# MKV10Z7 register map
File version: 1.6
Registers are 32-bit, read-write, reset 0x0 unless marked. A register's access mark holds for its fields unless they carry their own. Offsets are from the block's base; [hi:lo] are bit positions; {n}, {i} and the like mark numbered series; 'fields as' and 'values as' point back to an identical list.

## GPIOA — General Purpose Input/Output
Base 0x400FF000; register names take the prefix GPIOA_
0x00 PDOR — Port Data Output Register
  [31:0] PDO — Port Data Output
    0=Logic level 0 is driven on pin, provided pin is configured for general-purpose output; 1=Logic level 1 is driven on pin, provided pin is configured for general-purpose output
0x04 PSOR wo — Port Set Output Register
  [31:0] PTSO — Port Set Output
    0=Corresponding bit in PDORn does not change; 1=Corresponding bit in PDORn is set to logic 1
0x08 PCOR wo — Port Clear Output Register
  [31:0] PTCO — Port Clear Output
    0=Corresponding bit in PDORn does not change; 1=Corresponding bit in PDORn is cleared to logic 0
0x0C PTOR wo — Port Toggle Output Register
  [31:0] PTTO — Port Toggle Output
    0=Corresponding bit in PDORn does not change; 1=Corresponding bit in PDORn is set to the inverse of its existing logic state
0x10 PDIR ro — Port Data Input Register
  [31:0] PDI — Port Data Input
    0=Pin logic level is logic 0, or is not configured for use by digital function; 1=Pin logic level is logic 1
0x14 PDDR — Port Data Direction Register
  [31:0] PDD — Port Data Direction
    0=Pin is configured as general-purpose input, for the GPIO function; 1=Pin is configured as general-purpose output, for the GPIO function

## GPIOB — General Purpose Input/Output
Base 0x400FF040; register names take the prefix GPIOB_
Registers as GPIOA.

## GPIOC — General Purpose Input/Output
Base 0x400FF080; register names take the prefix GPIOC_
Registers as GPIOA.

## GPIOD — General Purpose Input/Output
Base 0x400FF0C0; register names take the prefix GPIOD_
Registers as GPIOA.

## GPIOE — General Purpose Input/Output
Base 0x400FF100; register names take the prefix GPIOE_
Registers as GPIOA.

## MTB — Micro Trace Buffer
Base 0xF0000000; register names take the prefix MTB_
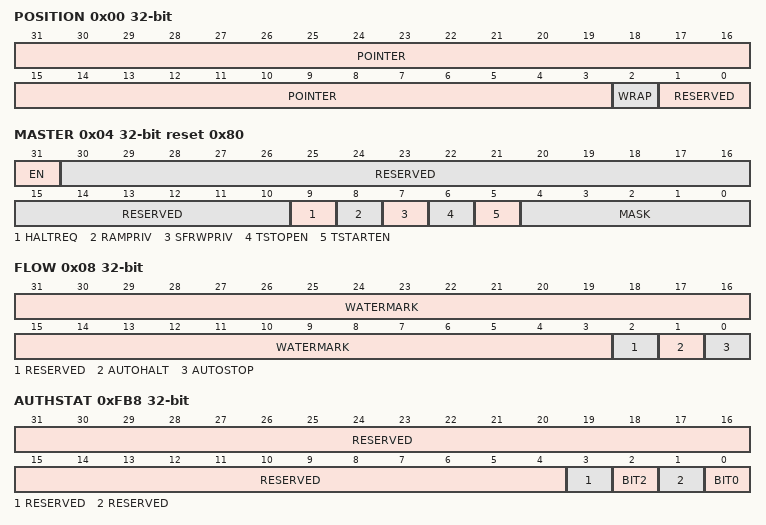
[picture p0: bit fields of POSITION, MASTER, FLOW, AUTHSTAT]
0x00 POSITION (reset mask 0x3) — MTB Position Register
  [31:3] POINTER — Trace Packet Address Pointer[28:0]
  [2] WRAP
  [1:0] RESERVED ro
0x04 MASTER reset 0x80 (reset mask 0xFFFFFFE0) — MTB Master Register
  [31] EN — Main Trace Enable
  [30:10] RESERVED ro
  [9] HALTREQ — Halt Request
  [8] RAMPRIV — RAM Privilege
  [7] SFRWPRIV — Special Function Register Write Privilege
  [6] TSTOPEN — Trace Stop Input Enable
  [5] TSTARTEN — Trace Start Input Enable
  [4:0] MASK
0x08 FLOW (reset mask 0x4) — MTB Flow Register
  [31:3] WATERMARK — WATERMARK[28:0]
  [2] RESERVED ro
  [1] AUTOHALT
  [0] AUTOSTOP
0x0C BASE ro reset not defined — MTB Base Register
  [31:0] BASEADDR
0xF00 MODECTRL ro — Integration Mode Control Register
0xFA0 TAGSET ro — Claim TAG Set Register
0xFA4 TAGCLEAR ro — Claim TAG Clear Register
0xFB0 LOCKACCESS ro
0xFB4 LOCKSTAT ro — Lock Status Register
0xFB8 AUTHSTAT ro — Authentication Status Register
  [31:4] RESERVED, [3] RESERVED, [2] BIT2, [1] RESERVED, [0] BIT0
0xFBC DEVICEARCH ro reset 0x47700A31 — Device Architecture Register
0xFC8 DEVICECFG ro — Device Configuration Register
0xFCC DEVICETYPID ro reset 0x31 — Device Type Identifier Register
0xFD0 PERIPHID{x} (x=4,5,6,7,0,1,2,3; step 0x4) ro reset not defined — Peripheral ID Register
  [31:0] PERIPHID
{0xFF0+4i} COMPID{i} (i=0..3) ro reset not defined — Component ID Register
  [31:0] COMPID — Component ID

## MTBDWT — MTB data watchpoint and trace
Base 0xF0001000; register names take the prefix MTBDWT_
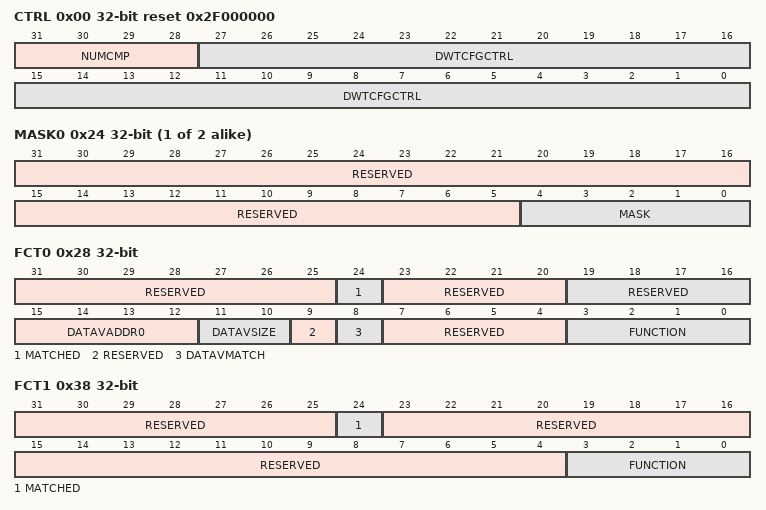
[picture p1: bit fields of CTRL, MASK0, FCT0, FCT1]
0x00 CTRL ro reset 0x2F000000 — MTB DWT Control Register
  [31:28] NUMCMP — Number of comparators
  [27:0] DWTCFGCTRL — DWT configuration controls
{0x20+0x10*i} COMP{i} (i=0..1) — MTB_DWT Comparator Register
  [31:0] COMP — Reference value for comparison
{0x24+0x10*i} MASK{i} (i=0..1) — MTB_DWT Comparator Mask Register
  [31:5] RESERVED ro, [4:0] MASK
0x28 FCT0 — MTB_DWT Comparator Function Register 0
  [31:25] RESERVED ro
  [24] MATCHED ro — Comparator match
    0=No match; 1=Match occurred
  [23:20] RESERVED ro
  [19:16] RESERVED ro
  [15:12] DATAVADDR0 — Data Value Address 0
  [11:10] DATAVSIZE — Data Value Size
    0=Byte; 1=Halfword; 2=Word; 3=Reserved. Any attempts to use this value results in UNPREDICTABLE behavior.
  [9] RESERVED ro
  [8] DATAVMATCH — Data Value Match
    0=Perform address comparison; 1=Perform data value comparison
  [7:4] RESERVED ro
  [3:0] FUNCTION
    0=Disabled; 4=Instruction fetch; 5=Data operand read; 6=Data operand write; 7=Data operand (read + write)
0x38 FCT1 — MTB_DWT Comparator Function Register 1
  [31:25] RESERVED ro
  [24] MATCHED ro — Comparator match
    0=No match; 1=Match occurred
  [23:4] RESERVED ro
  [3:0] FUNCTION
    values as FCT0.FUNCTION
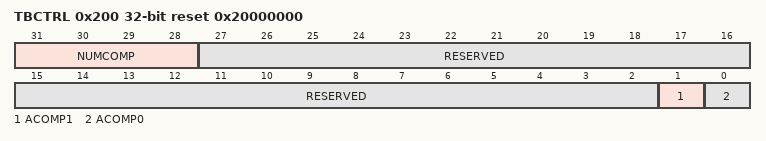
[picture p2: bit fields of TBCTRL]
0x200 TBCTRL reset 0x20000000 — MTB_DWT Trace Buffer Control Register
  [31:28] NUMCOMP ro — Number of Comparators
  [27:2] RESERVED ro
  [1] ACOMP1 — Action based on Comparator 1 match
    0=Trigger TSTOP based on the assertion of MTBDWT_FCT1[MATCHED]; 1=Trigger TSTART based on the assertion of MTBDWT_FCT1[MATCHED]
  [0] ACOMP0 — Action based on Comparator 0 match
    0=Trigger TSTOP based on the assertion of MTBDWT_FCT0[MATCHED]; 1=Trigger TSTART based on the assertion of MTBDWT_FCT0[MATCHED]
0xFC8 DEVICECFG ro — Device Configuration Register
0xFCC DEVICETYPID ro reset 0x4 — Device Type Identifier Register
0xFD0 PERIPHID{x} (x=4,5,6,7,0,1,2,3; step 0x4) ro reset not defined — Peripheral ID Register
  [31:0] PERIPHID
{0xFF0+4i} COMPID{i} (i=0..3) ro reset not defined — Component ID Register
  [31:0] COMPID — Component ID
